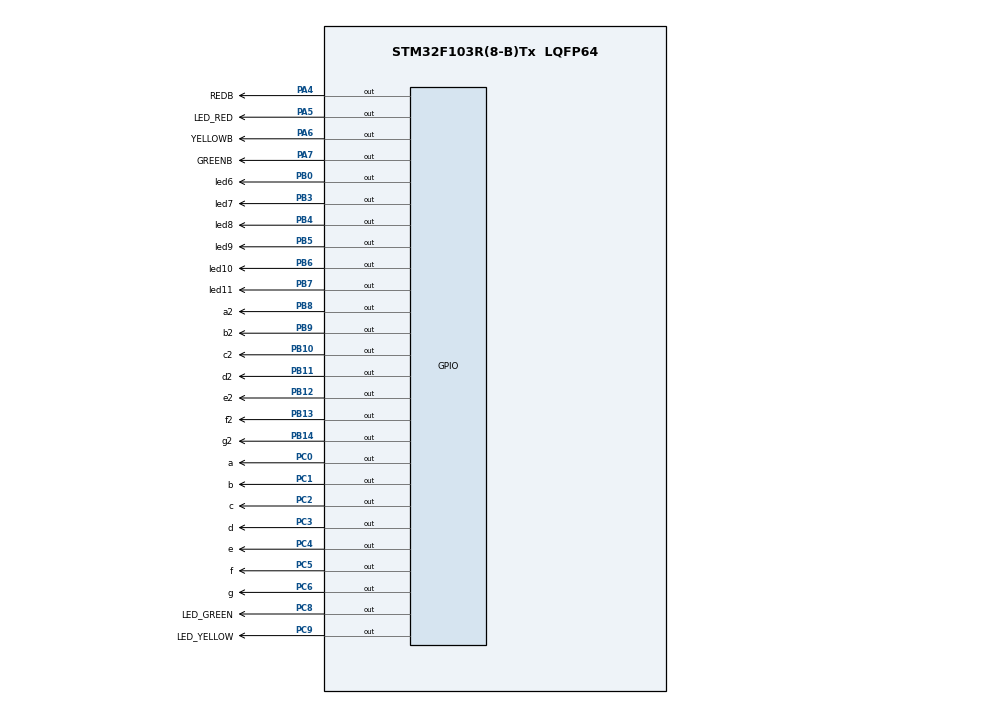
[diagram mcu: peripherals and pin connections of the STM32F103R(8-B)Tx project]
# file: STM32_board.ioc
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Mcu.Family=STM32F1
Mcu.Name=STM32F103R(8-B)Tx
Mcu.Package=LQFP64
NVIC.PriorityGroup=NVIC_PRIORITYGROUP_4
PA13.GPIO_Label=TMS
PA13.Mode=Serial_Wire
PA13.Signal=SYS_JTMS-SWDIO
PA14.GPIO_Label=TCK
PA14.Mode=Serial_Wire
PA14.Signal=SYS_JTCK-SWCLK
PA4.GPIO_Label=REDB
PA4.Signal=GPIO_Output
PA5.GPIO_Label=LED_RED
PA5.Signal=GPIO_Output
PA6.GPIO_Label=YELLOWB
PA6.Signal=GPIO_Output
PA7.GPIO_Label=GREENB
PA7.Signal=GPIO_Output
PB0.GPIO_Label=led6
PB0.Signal=GPIO_Output
PB10.GPIO_Label=c2
PB10.Signal=GPIO_Output
PB11.GPIO_Label=d2
PB11.Signal=GPIO_Output
PB12.GPIO_Label=e2
PB12.Signal=GPIO_Output
PB13.GPIO_Label=f2
PB13.Signal=GPIO_Output
PB14.GPIO_Label=g2
PB14.Signal=GPIO_Output
PB3.GPIO_Label=led7
PB3.Signal=GPIO_Output
PB4.GPIO_Label=led8
PB4.Signal=GPIO_Output
PB5.GPIO_Label=led9
PB5.Signal=GPIO_Output
PB6.GPIO_Label=led10
PB6.Signal=GPIO_Output
PB7.GPIO_Label=led11
PB7.Signal=GPIO_Output
PB8.GPIO_Label=a2
PB8.Signal=GPIO_Output
PB9.GPIO_Label=b2
PB9.Signal=GPIO_Output
PC0.GPIO_Label=a
PC0.Signal=GPIO_Output
PC1.GPIO_Label=b
PC1.Signal=GPIO_Output
PC14-OSC32_IN.Mode=LSE-External-Clock-Source
PC14-OSC32_IN.Signal=RCC_OSC32_IN
PC15-OSC32_OUT.Mode=LSE-External-Clock-Source
PC15-OSC32_OUT.Signal=RCC_OSC32_OUT
PC2.GPIO_Label=c
PC2.Signal=GPIO_Output
PC3.GPIO_Label=d
PC3.Signal=GPIO_Output
PC4.GPIO_Label=e
PC4.Signal=GPIO_Output
PC5.GPIO_Label=f
PC5.Signal=GPIO_Output
PC6.GPIO_Label=g
PC6.Signal=GPIO_Output
PC8.GPIO_Label=LED_GREEN
PC8.Signal=GPIO_Output
PC9.GPIO_Label=LED_YELLOW
PC9.Signal=GPIO_Output
PD0-OSC_IN.Mode=HSE-External-Clock-Source
PD0-OSC_IN.Signal=RCC_OSC_IN
PD1-OSC_OUT.Mode=HSE-External-Clock-Source
PD1-OSC_OUT.Signal=RCC_OSC_OUT
ProjectManager.HeapSize=0x200
ProjectManager.StackSize=0x400
ProjectManager.TargetToolchain=STM32CubeIDE
RCC.APB1Freq_Value=8000000
RCC.APB2Freq_Value=8000000
board=custom

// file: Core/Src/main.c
/* USER CODE BEGIN Header */
/**
  ******************************************************************************
  * @file           : main.c
  * @brief          : Main program body
  ******************************************************************************
  * @attention
  *
  * <h2><center>&copy; Copyright (c) 2024 STMicroelectronics.
  * All rights reserved.</center></h2>
  *
  * This software component is licensed by ST under BSD 3-Clause license,
  * the "License"; You may not use this file except in compliance with the
  * License. You may obtain a copy of the License at:
  *                        opensource.org/licenses/BSD-3-Clause
  *
  ******************************************************************************
  */
/* USER CODE END Header */
#include "main.h"

/* USER CODE BEGIN Includes */
//#include "exercise1.h"
//#include "exercise2.h"
//#include "exercise3.h"
//#include "exercise4.h"
//#include "exercise5.h"
#include "exercise10.h"
/* USER CODE END Includes */

void SystemClock_Config(void);
static void MX_GPIO_Init(void);

int main(void)
{

  /* MCU Configuration--------------------------------------------------------*/

  /* Reset of all peripherals, Initializes the Flash interface and the Systick. */
  HAL_Init();

  /* Configure the system clock */
  SystemClock_Config();

  /* Initialize all configured peripherals */
  MX_GPIO_Init();

  /* Infinite loop */
  /* USER CODE BEGIN WHILE */
  //init_exercise1();
  //init_exercise2();
  //init_exercise3();
  //init_exercise4();
  //int counter = 0;
  //init_exercise5();
  init_exercise10();
  while (1)
  {
	  //exercise1_run();
	  //exercise2_run();
	  //exercise3_run();
	  //if(counter>=10)counter = 0;
	  //display7SEG(counter++);
	  //exercise5_run();
	  exercise10_run();
	  HAL_Delay(1000);
    /* USER CODE END WHILE */

  }
}

void SystemClock_Config(void)
{
  RCC_OscInitTypeDef RCC_OscInitStruct = {0};
  RCC_ClkInitTypeDef RCC_ClkInitStruct = {0};

  /** Initializes the RCC Oscillators according to the specified parameters
  * in the RCC_OscInitTypeDef structure.
  */
  RCC_OscInitStruct.OscillatorType = RCC_OSCILLATORTYPE_HSI;
  RCC_OscInitStruct.HSIState = RCC_HSI_ON;
  RCC_OscInitStruct.HSICalibrationValue = RCC_HSICALIBRATION_DEFAULT;
  RCC_OscInitStruct.PLL.PLLState = RCC_PLL_NONE;
  if (HAL_RCC_OscConfig(&RCC_OscInitStruct) != HAL_OK)
  {
    Error_Handler();
  }
  /** Initializes the CPU, AHB and APB buses clocks
  */
  RCC_ClkInitStruct.ClockType = RCC_CLOCKTYPE_HCLK|RCC_CLOCKTYPE_SYSCLK
                              |RCC_CLOCKTYPE_PCLK1|RCC_CLOCKTYPE_PCLK2;
  RCC_ClkInitStruct.SYSCLKSource = RCC_SYSCLKSOURCE_HSI;
  RCC_ClkInitStruct.AHBCLKDivider = RCC_SYSCLK_DIV1;
  RCC_ClkInitStruct.APB1CLKDivider = RCC_HCLK_DIV1;
  RCC_ClkInitStruct.APB2CLKDivider = RCC_HCLK_DIV1;

  if (HAL_RCC_ClockConfig(&RCC_ClkInitStruct, FLASH_LATENCY_0) != HAL_OK)
  {
    Error_Handler();
  }
}

static void MX_GPIO_Init(void)
{
  GPIO_InitTypeDef GPIO_InitStruct = {0};

  /* GPIO Ports Clock Enable */
  __HAL_RCC_GPIOC_CLK_ENABLE();
  __HAL_RCC_GPIOD_CLK_ENABLE();
  __HAL_RCC_GPIOA_CLK_ENABLE();
  __HAL_RCC_GPIOB_CLK_ENABLE();

  /*Configure GPIO pin Output Level */
  HAL_GPIO_WritePin(GPIOC, a_Pin|b_Pin|c_Pin|d_Pin
                          |e_Pin|f_Pin|g_Pin|LED_GREEN_Pin
                          |LED_YELLOW_Pin, GPIO_PIN_RESET);

  /*Configure GPIO pin Output Level */
  HAL_GPIO_WritePin(GPIOA, REDB_Pin|LED_RED_Pin|YELLOWB_Pin|GREENB_Pin, GPIO_PIN_RESET);

  /*Configure GPIO pin Output Level */
  HAL_GPIO_WritePin(GPIOB, led6_Pin|c2_Pin|d2_Pin|e2_Pin
                          |f2_Pin|g2_Pin|led7_Pin|led8_Pin
                          |led9_Pin|led10_Pin|led11_Pin|a2_Pin
                          |b2_Pin, GPIO_PIN_RESET);

  /*Configure GPIO pins : a_Pin b_Pin c_Pin d_Pin
                           e_Pin f_Pin g_Pin LED_GREEN_Pin
                           LED_YELLOW_Pin */
  GPIO_InitStruct.Pin = a_Pin|b_Pin|c_Pin|d_Pin
                          |e_Pin|f_Pin|g_Pin|LED_GREEN_Pin
                          |LED_YELLOW_Pin;
  GPIO_InitStruct.Mode = GPIO_MODE_OUTPUT_PP;
  GPIO_InitStruct.Pull = GPIO_NOPULL;
  GPIO_InitStruct.Speed = GPIO_SPEED_FREQ_LOW;
  HAL_GPIO_Init(GPIOC, &GPIO_InitStruct);

  /*Configure GPIO pins : REDB_Pin LED_RED_Pin YELLOWB_Pin GREENB_Pin */
  GPIO_InitStruct.Pin = REDB_Pin|LED_RED_Pin|YELLOWB_Pin|GREENB_Pin;
  GPIO_InitStruct.Mode = GPIO_MODE_OUTPUT_PP;
  GPIO_InitStruct.Pull = GPIO_NOPULL;
  GPIO_InitStruct.Speed = GPIO_SPEED_FREQ_LOW;
  HAL_GPIO_Init(GPIOA, &GPIO_InitStruct);

  /*Configure GPIO pins : led6_Pin c2_Pin d2_Pin e2_Pin
                           f2_Pin g2_Pin led7_Pin led8_Pin
                           led9_Pin led10_Pin led11_Pin a2_Pin
                           b2_Pin */
  GPIO_InitStruct.Pin = led6_Pin|c2_Pin|d2_Pin|e2_Pin
                          |f2_Pin|g2_Pin|led7_Pin|led8_Pin
                          |led9_Pin|led10_Pin|led11_Pin|a2_Pin
                          |b2_Pin;
  GPIO_InitStruct.Mode = GPIO_MODE_OUTPUT_PP;
  GPIO_InitStruct.Pull = GPIO_NOPULL;
  GPIO_InitStruct.Speed = GPIO_SPEED_FREQ_LOW;
  HAL_GPIO_Init(GPIOB, &GPIO_InitStruct);

}

void Error_Handler(void)
{
  __disable_irq();
  while (1)
  {
  }
}

/************************ (C) COPYRIGHT STMicroelectronics *****END OF FILE****/
